LIN_description_file;
LIN_protocol_version = "2.1";
LIN_language_version = "2.1";
LIN_speed = 19.2 kbps;

Nodes {
  Master: LIN_Master, 1 ms, 0 ms ;
  Slaves: Yueting ;
}

Signals {
  YT_SENT_Position: 16, 0, Yueting, LIN_Master ;
  MASTER_ModeCommand: 8, 0, LIN_Master, Yueting ;
  MASTER_TargetPosition: 16, 0, LIN_Master, Yueting ;
  YT_SENT_Angle: 16, 0, Yueting, LIN_Master ;
  YT_CAL_Mode: 8, 0, Yueting, LIN_Master ;
  YT_CAL_FirstPos: 16, 0, Yueting, LIN_Master ;
  YT_CAL_SecondPos: 16, 0, Yueting, LIN_Master ;
  YT_CAL_Enable: 8, 0, Yueting, LIN_Master ;
  MASTER_CAL_Mode: 8, 0, LIN_Master, Yueting ;
  MASTER_CAL_FirstPos: 16, 0, LIN_Master, Yueting ;
  MASTER_CAL_SecondPos: 16, 0, LIN_Master, Yueting ;
  MASTER_CAL_Enable: 8, 0, LIN_Master, Yueting ;
}

Frames {
  YT_SENT: 3, Yueting, 8 {
    YT_SENT_Position, 0 ;
    YT_SENT_Angle, 16 ;
  }
  MASTER: 4, LIN_Master, 8 {
    MASTER_ModeCommand, 0 ;
    MASTER_TargetPosition, 8 ;
  }
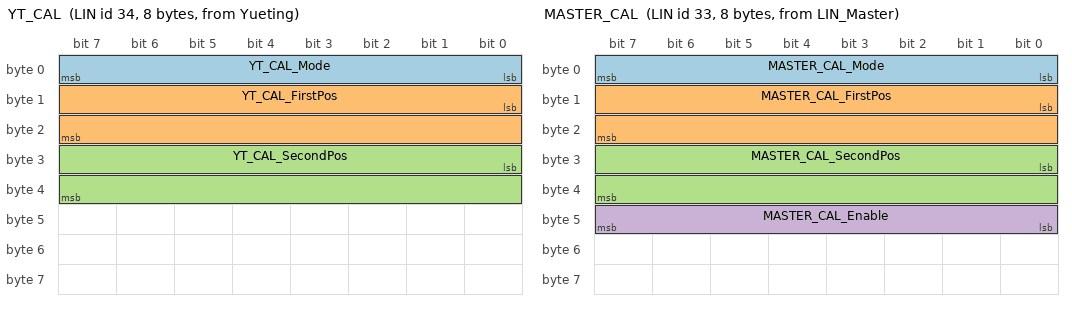
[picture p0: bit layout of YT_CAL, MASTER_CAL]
  YT_CAL: 34, Yueting, 8 {
    YT_CAL_Mode, 0 ;
    YT_CAL_FirstPos, 8 ;
    YT_CAL_SecondPos, 24 ;
  }
  MASTER_CAL: 33, LIN_Master, 8 {
    MASTER_CAL_Mode, 0 ;
    MASTER_CAL_FirstPos, 8 ;
    MASTER_CAL_SecondPos, 24 ;
    MASTER_CAL_Enable, 40 ;
  }
}

Node_attributes {
  Yueting{
    LIN_protocol = "2.1" ;
    configured_NAD = 0xFF ;
    initial_NAD = 0xFF ;
    product_id = 0x0, 0x0, 255 ;
    P2_min = 50 ms ;
    ST_min = 0 ms ;
    N_As_timeout = 1000 ms ;
    N_Cr_timeout = 1000 ms ;
    configurable_frames {
      YT_SENT ;
      MASTER ;
      YT_CAL ;
      MASTER_CAL ;
    }
  }
}

Schedule_tables {
 ScheduleTable {
    YT_SENT delay 10 ms ;
    MASTER delay 10 ms ;
    MASTER_CAL delay 10 ms ;
    YT_CAL delay 10 ms ;
  }
}

Signal_encoding_types {
  YTSENTAngleEncoding {
    physical_value, 0, 3600, 0.1, 0 ;
  }
}

Signal_representation {
  YTSENTAngleEncoding: YT_SENT_Angle ;
}
